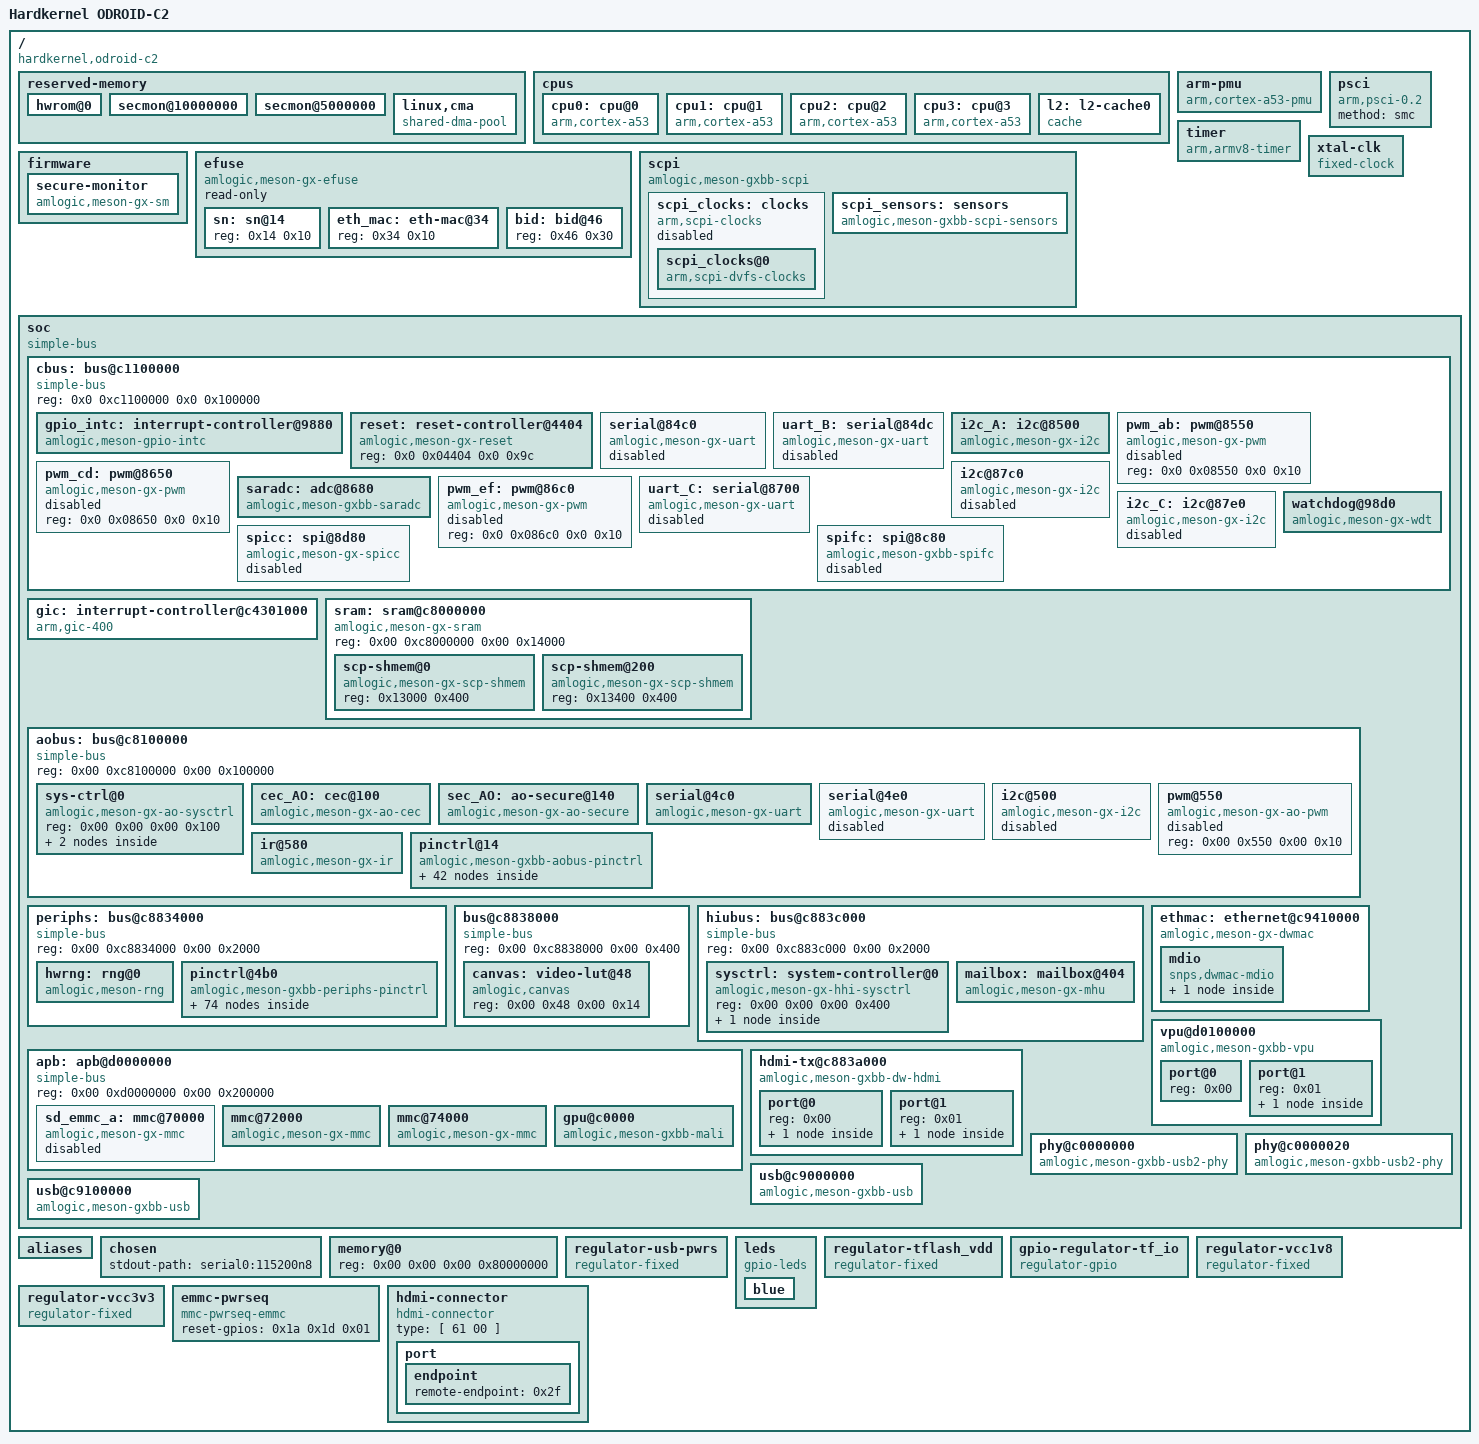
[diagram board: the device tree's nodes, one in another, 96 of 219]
/*
 * Copyright Linux Kernel Team
 *
 * SPDX-License-Identifier: GPL-2.0-only
 *
 * This file is derived from an intermediate build stage of the
 * Linux kernel. The licenses of all input files to this process
 * are compatible with GPL-2.0-only.
 */

/dts-v1/;

/ {
	interrupt-parent = < 0x01 >;
	#address-cells = < 0x02 >;
	#size-cells = < 0x02 >;
	compatible = "hardkernel,odroid-c2", "amlogic,meson-gxbb";
	model = "Hardkernel ODROID-C2";

	reserved-memory {
		#address-cells = <2>;
		#size-cells = <2>;
		ranges;

		/* 16 MiB reserved for Hardware ROM Firmware */
		hwrom@0 {
			reg = < 0x00 0x00 0x00 0x1000000 >;
			no-map;
		};

        /* 2 MiB reserved for ATF/BL31 */
        secmon@10000000 {
			reg = < 0x00 0x10000000 0x00 0x200000 >;
			no-map;
		};

        /* 35 MiB reserved for ATF and TrustZone OS */
		secmon@5000000 {
			reg = < 0x00 0x5000000 0x00 0x2300000 >;
			no-map;
		};

		linux,cma {
			compatible = "shared-dma-pool";
			reusable;
			size = <0x0 0x10000000>;
			alignment = <0x0 0x400000>;
			linux,cma-default;
		};
	};

	cpus {
		#address-cells = <0x2>;
		#size-cells = <0x0>;

		cpu0: cpu@0 {
			device_type = "cpu";
			compatible = "arm,cortex-a53", "arm,armv8";
			reg = <0x0 0x0>;
			enable-method = "psci";
			next-level-cache = < 0x02 >;
			clocks = < 0x03 0x00 >;
			phandle = < 0x04 >;
		};

		cpu1: cpu@1 {
			device_type = "cpu";
			compatible = "arm,cortex-a53", "arm,armv8";
			reg = <0x0 0x1>;
			enable-method = "psci";
			next-level-cache = < 0x02 >;
			clocks = < 0x03 0x00 >;
			phandle = < 0x05 >;
		};

		cpu2: cpu@2 {
			device_type = "cpu";
			compatible = "arm,cortex-a53", "arm,armv8";
			reg = <0x0 0x2>;
			enable-method = "psci";
			next-level-cache = < 0x02 >;
			clocks = < 0x03 0x00 >;
			phandle = < 0x06 >;
		};

		cpu3: cpu@3 {
			device_type = "cpu";
			compatible = "arm,cortex-a53", "arm,armv8";
			reg = < 0x00 0x03 >;
			enable-method = "psci";
			next-level-cache = < 0x02 >;
			clocks = < 0x03 0x00 >;
			phandle = < 0x07 >;
		};

		l2: l2-cache0 {
			compatible = "cache";
			phandle = < 0x02 >;
		};
	};

	arm-pmu {
		compatible = "arm,cortex-a53-pmu";
		interrupts = < 0x00 0x89 0x04 0x00 0x8a 0x04 0x00 0x99 0x04 0x00 0x9a 0x04 >;
		interrupt-affinity = < 0x04 0x05 0x06 0x07 >;
	};

	psci {
		compatible = "arm,psci-0.2";
		method = "smc";
	};

	timer {
		compatible = "arm,armv8-timer";
		interrupts = < 0x01 0x0d 0xff08 0x01 0x0e 0xff08 0x01 0x0b 0xff08 0x01 0x0a 0xff08 >;
	};

	xtal-clk {
		compatible = "fixed-clock";
		clock-frequency = < 0x16e3600 >;
		clock-output-names = "xtal";
		#clock-cells = <0>;
		phandle = < 0x0b >;
	};

	firmware {

		secure-monitor {
			compatible = "amlogic,meson-gx-sm", "amlogic,meson-gxbb-sm";
		};
	};

	efuse: efuse {
		compatible = "amlogic,meson-gx-efuse", "amlogic,meson-gxbb-efuse";
		#address-cells = <1>;
		#size-cells = <1>;
		read-only;

		sn: sn@14 {
			reg = <0x14 0x10>;
		};

		eth_mac: eth-mac@34 {
			reg = <0x34 0x10>;
		};

		bid: bid@46 {
			reg = <0x46 0x30>;
		};
	};

	scpi {
		compatible = "amlogic,meson-gxbb-scpi", "arm,scpi-pre-1.0";
		mboxes = < 0x08 0x01 0x08 0x02 >;
		shmem = < 0x09 0x0a >;

		scpi_clocks: clocks {
			compatible = "arm,scpi-clocks";
			status = "disabled";

			scpi_clocks@0 {
				compatible = "arm,scpi-dvfs-clocks";
				#clock-cells = <1>;
				clock-indices = <0>;
				clock-output-names = "vcpu";
				phandle = < 0x03 >;
			};
		};

		scpi_sensors: sensors {
			compatible = "amlogic,meson-gxbb-scpi-sensors", "arm,scpi-sensors";
			#thermal-sensor-cells = <1>;
		};
	};

	soc {
		compatible = "simple-bus";
		#address-cells = <2>;
		#size-cells = <2>;
		ranges;

		cbus: bus@c1100000 {
			compatible = "simple-bus";
			reg = <0x0 0xc1100000 0x0 0x100000>;
			#address-cells = <2>;
			#size-cells = <2>;
			ranges = <0x0 0x0 0x0 0xc1100000 0x0 0x100000>;

			gpio_intc: interrupt-controller@9880 {
				compatible = "amlogic,meson-gpio-intc", "amlogic,meson-gxbb-gpio-intc";
				reg = <0x0 0x9880 0x0 0x10>;
				interrupt-controller;
				#interrupt-cells = <2>;
				amlogic,channel-interrupts = < 0x40 0x41 0x42 0x43 0x44 0x45 0x46 0x47 >;
				status = "okay";
				phandle = < 0x1b >;
			};

			reset: reset-controller@4404 {
				compatible = "amlogic,meson-gx-reset", "amlogic,meson-gxbb-reset";
				reg = <0x0 0x04404 0x0 0x9c>;
				#reset-cells = <1>;
				phandle = < 0x0f >;
			};

			serial@84c0 {
				compatible = "amlogic,meson-gx-uart";
				reg = <0x0 0x84c0 0x0 0x18>;
				interrupts = < 0x00 0x1a 0x01 >;
				status = "disabled";
				clocks = < 0x0b 0x0c 0x1a 0x0b >;
				clock-names = "xtal", "pclk", "baud";
			};

			uart_B: serial@84dc {
				compatible = "amlogic,meson-gx-uart";
				reg = <0x0 0x84dc 0x0 0x18>;
				interrupts = < 0x00 0x4b 0x01 >;
				status = "disabled";
				clocks = < 0x0b 0x0c 0x30 0x0b >;
				clock-names = "xtal", "pclk", "baud";
			};

			i2c_A: i2c@8500 {
				compatible = "amlogic,meson-gx-i2c", "amlogic,meson-gxbb-i2c";
				reg = <0x0 0x08500 0x0 0x20>;
				interrupts = < 0x00 0x15 0x01 >;
				#address-cells = < 0x01 >;
				#size-cells = <0>;
				status = "okay";
				clocks = < 0x0c 0x16 >;
				pinctrl-0 = < 0x0d >;
				pinctrl-names = "default";
			};

			pwm_ab: pwm@8550 {
				compatible = "amlogic,meson-gx-pwm", "amlogic,meson-gxbb-pwm";
				reg = <0x0 0x08550 0x0 0x10>;
				#pwm-cells = <3>;
				status = "disabled";
			};

			pwm_cd: pwm@8650 {
				compatible = "amlogic,meson-gx-pwm", "amlogic,meson-gxbb-pwm";
				reg = <0x0 0x08650 0x0 0x10>;
				#pwm-cells = <3>;
				status = "disabled";
			};

			saradc: adc@8680 {
				compatible = "amlogic,meson-gxbb-saradc", "amlogic,meson-saradc";
				reg = <0x0 0x8680 0x0 0x34>;
				#io-channel-cells = <1>;
				interrupts = < 0x00 0x49 0x01 >;
				status = "okay";
				clocks = < 0x0b 0x0c 0x17 0x0c 0x61 0x0c 0x62 >;
				clock-names = "clkin", "core", "adc_clk", "adc_sel";
				vref-supply = < 0x0e >;
			};

			pwm_ef: pwm@86c0 {
				compatible = "amlogic,meson-gx-pwm", "amlogic,meson-gxbb-pwm";
				reg = <0x0 0x086c0 0x0 0x10>;
				#pwm-cells = <3>;
				status = "disabled";
			};

			uart_C: serial@8700 {
				compatible = "amlogic,meson-gx-uart";
				reg = <0x0 0x8700 0x0 0x18>;
				interrupts = < 0x00 0x5d 0x01 >;
				status = "disabled";
				clocks = < 0x0b 0x0c 0x44 0x0b >;
				clock-names = "xtal", "pclk", "baud";
			};

			i2c@87c0 {
				compatible = "amlogic,meson-gx-i2c", "amlogic,meson-gxbb-i2c";
				reg = < 0x00 0x87c0 0x00 0x20 >;
				interrupts = < 0x00 0xd6 0x01 >;
				#address-cells = < 0x01 >;
				#size-cells = < 0x00 >;
				status = "disabled";
				clocks = < 0x0c 0x16 >;
			};

			i2c_C: i2c@87e0 {
				compatible = "amlogic,meson-gx-i2c", "amlogic,meson-gxbb-i2c";
				reg = < 0x00 0x87e0 0x00 0x20 >;
				interrupts = < 0x00 0xd7 0x01 >;
				#address-cells = < 0x01 >;
				#size-cells = < 0x00 >;
				status = "disabled";
				clocks = < 0x0c 0x16 >;
			};

			spicc: spi@8d80 {
				compatible = "amlogic,meson-gx-spicc";
				reg = < 0x00 0x8d80 0x00 0x80 >;
				interrupts = < 0x00 0x51 0x04 >;
				#address-cells = < 0x01 >;
				#size-cells = < 0x00 >;
				status = "disabled";
				clocks = < 0x0c 0x15 >;
				clock-names = "core";
				resets = < 0x0f 0xc1 >;
				num-cs = < 0x01 >;
			};

			spifc: spi@8c80 {
				compatible = "amlogic,meson-gxbb-spifc";
				reg = < 0x00 0x8c80 0x00 0x80 >;
				#address-cells = < 0x01 >;
				#size-cells = < 0x00 >;
				status = "disabled";
				clocks = < 0x0c 0x22 >;
			};

			watchdog@98d0 {
				compatible = "amlogic,meson-gx-wdt", "amlogic,meson-gxbb-wdt";
				reg = < 0x00 0x98d0 0x00 0x10 >;
				clocks = < 0x0b >;
			};
		};

		gic: interrupt-controller@c4301000 {
			compatible = "arm,gic-400";
			reg = < 0x00 0xc4301000 0x00 0x1000 0x00 0xc4302000 0x00 0x2000 0x00 0xc4304000 0x00 0x2000 0x00 0xc4306000 0x00 0x2000 >;
			interrupt-controller;
			interrupts = < 0x01 0x09 0xff04 >;
			#interrupt-cells = < 0x03 >;
			#address-cells = < 0x00 >;
			phandle = < 0x01 >;
		};

		sram: sram@c8000000 {
			compatible = "amlogic,meson-gx-sram", "amlogic,meson-gxbb-sram", "mmio-sram";
			reg = < 0x00 0xc8000000 0x00 0x14000 >;
			#address-cells = < 0x01 >;
			#size-cells = < 0x01 >;
			ranges = < 0x00 0x00 0xc8000000 0x14000 >;

			scp-shmem@0 {
				compatible = "amlogic,meson-gx-scp-shmem", "amlogic,meson-gxbb-scp-shmem";
				reg = < 0x13000 0x400 >;
				phandle = < 0x09 >;
			};

			scp-shmem@200 {
				compatible = "amlogic,meson-gx-scp-shmem", "amlogic,meson-gxbb-scp-shmem";
				reg = < 0x13400 0x400 >;
				phandle = < 0x0a >;
			};
		};

		aobus: bus@c8100000 {
			compatible = "simple-bus";
			reg = < 0x00 0xc8100000 0x00 0x100000 >;
			#address-cells = < 0x02 >;
			#size-cells = < 0x02 >;
			ranges = < 0x00 0x00 0x00 0xc8100000 0x00 0x100000 >;

			sys-ctrl@0 {
				compatible = "amlogic,meson-gx-ao-sysctrl", "simple-mfd", "syscon";
				reg = < 0x00 0x00 0x00 0x100 >;

				power-controller-vpu {
					compatible = "amlogic,meson-gx-pwrc-vpu";
					#power-domain-cells = < 0x00 >;
					amlogic,hhi-sysctrl = < 0x10 >;
					resets = < 0x0f 0x05 0x0f 0x0a 0x0f 0x0d 0x0f 0x25 0x0f 0x84 0x0f 0x85 0x0f 0x86 0x0f 0x87 0x0f 0x89 0x0f 0x8c 0x0f 0x8d 0x0f 0xe7 >;
					clocks = < 0x0c 0x84 0x0c 0x8c >;
					clock-names = "vpu", "vapb";
					assigned-clocks = < 0x0c 0x7e 0x0c 0x80 0x0c 0x84 0x0c 0x85 0x0c 0x87 0x0c 0x8b >;
					assigned-clock-parents = < 0x0c 0x05 0x00 0x0c 0x80 0x0c 0x06 0x00 0x0c 0x87 >;
					assigned-clock-rates = < 0x00 0x27bc86aa 0x00 0x00 0xee6b280 0x00 >;
					phandle = < 0x25 >;
				};

				clkc_AO: clock-controller {
					compatible = "amlogic,meson-gxbb-aoclkc", "amlogic,meson-gx-aoclkc";
					#clock-cells = < 0x01 >;
					#reset-cells = < 0x01 >;
					phandle = < 0x11 >;
				};
			};

			cec_AO: cec@100 {
				compatible = "amlogic,meson-gx-ao-cec";
				reg = < 0x00 0x100 0x00 0x14 >;
				interrupts = < 0x00 0xc7 0x01 >;
				clocks = < 0x11 0x06 >;
				clock-names = "core";
				status = "okay";
				pinctrl-0 = < 0x12 >;
				pinctrl-names = "default";
				hdmi-phandle = < 0x13 >;
			};

			sec_AO: ao-secure@140 {
				compatible = "amlogic,meson-gx-ao-secure", "syscon";
				reg = < 0x00 0x140 0x00 0x140 >;
				amlogic,has-chip-id;
			};

			serial@4c0 {
				compatible = "amlogic,meson-gx-uart", "amlogic,meson-ao-uart";
				reg = < 0x00 0x4c0 0x00 0x18 >;
				interrupts = < 0x00 0xc1 0x01 >;
				status = "okay";
				clocks = < 0x0b 0x11 0x03 0x0b >;
				clock-names = "xtal", "pclk", "baud";
				pinctrl-0 = < 0x14 >;
				pinctrl-names = "default";
			};

			serial@4e0 {
				compatible = "amlogic,meson-gx-uart", "amlogic,meson-ao-uart";
				reg = < 0x00 0x4e0 0x00 0x18 >;
				interrupts = < 0x00 0xc5 0x01 >;
				status = "disabled";
				clocks = < 0x0b 0x11 0x04 0x0b >;
				clock-names = "xtal", "pclk", "baud";
			};

			i2c@500 {
				compatible = "amlogic,meson-gx-i2c", "amlogic,meson-gxbb-i2c";
				reg = < 0x00 0x500 0x00 0x20 >;
				interrupts = < 0x00 0xc3 0x01 >;
				#address-cells = < 0x01 >;
				#size-cells = < 0x00 >;
				status = "disabled";
				clocks = < 0x0c 0x5d >;
			};

			pwm@550 {
				compatible = "amlogic,meson-gx-ao-pwm", "amlogic,meson-gxbb-ao-pwm";
				reg = < 0x00 0x550 0x00 0x10 >;
				#pwm-cells = < 0x03 >;
				status = "disabled";
			};

			ir@580 {
				compatible = "amlogic,meson-gx-ir", "amlogic,meson-gxbb-ir";
				reg = < 0x00 0x580 0x00 0x40 >;
				interrupts = < 0x00 0xc4 0x01 >;
				status = "okay";
				pinctrl-0 = < 0x15 >;
				pinctrl-names = "default";
			};

			pinctrl@14 {
				compatible = "amlogic,meson-gxbb-aobus-pinctrl";
				#address-cells = < 0x02 >;
				#size-cells = < 0x02 >;
				ranges;
				gpio-line-names = "UART TX", "UART RX", "VCCK En", "TF 3V3/1V8 En", "USB HUB nRESET", "USB OTG Power En", "J7 Header Pin2", "IR In", "J7 Header Pin4", "J7 Header Pin6", "J7 Header Pin5", "J7 Header Pin7", "HDMI CEC", "SYS LED", "";
				phandle = < 0x16 >;

				bank@14 {
					reg = < 0x00 0x14 0x00 0x08 0x00 0x2c 0x00 0x04 0x00 0x24 0x00 0x08 >;
					reg-names = "mux", "pull", "gpio";
					gpio-controller;
					#gpio-cells = < 0x02 >;
					gpio-ranges = < 0x16 0x00 0x00 0x0e >;
					phandle = < 0x2e >;

					usb-hub {
						gpio-hog;
						gpios = < 0x04 0x00 >;
						output-high;
						line-name = "usb-hub-reset";
					};
				};

				uart_ao_a {
					phandle = < 0x14 >;

					mux {
						groups = "uart_tx_ao_a", "uart_rx_ao_a";
						function = "uart_ao";
					};
				};

				uart_ao_a_cts_rts {

					mux {
						groups = "uart_cts_ao_a", "uart_rts_ao_a";
						function = "uart_ao";
					};
				};

				uart_ao_b {

					mux {
						groups = "uart_tx_ao_b", "uart_rx_ao_b";
						function = "uart_ao_b";
					};
				};

				uart_ao_b_cts_rts {

					mux {
						groups = "uart_cts_ao_b", "uart_rts_ao_b";
						function = "uart_ao_b";
					};
				};

				remote_input_ao {
					phandle = < 0x15 >;

					mux {
						groups = "remote_input_ao";
						function = "remote_input_ao";
					};
				};

				i2c_ao {

					mux {
						groups = "i2c_sck_ao", "i2c_sda_ao";
						function = "i2c_ao";
					};
				};

				pwm_ao_a_3 {

					mux {
						groups = "pwm_ao_a_3";
						function = "pwm_ao_a_3";
					};
				};

				pwm_ao_a_6 {

					mux {
						groups = "pwm_ao_a_6";
						function = "pwm_ao_a_6";
					};
				};

				pwm_ao_a_12 {

					mux {
						groups = "pwm_ao_a_12";
						function = "pwm_ao_a_12";
					};
				};

				pwm_ao_b {

					mux {
						groups = "pwm_ao_b";
						function = "pwm_ao_b";
					};
				};

				i2s_am_clk {

					mux {
						groups = "i2s_am_clk";
						function = "i2s_out_ao";
					};
				};

				i2s_out_ao_clk {

					mux {
						groups = "i2s_out_ao_clk";
						function = "i2s_out_ao";
					};
				};

				i2s_out_lr_clk {

					mux {
						groups = "i2s_out_lr_clk";
						function = "i2s_out_ao";
					};
				};

				i2s_out_ch01_ao {

					mux {
						groups = "i2s_out_ch01_ao";
						function = "i2s_out_ao";
					};
				};

				i2s_out_ch23_ao {

					mux {
						groups = "i2s_out_ch23_ao";
						function = "i2s_out_ao";
					};
				};

				i2s_out_ch45_ao {

					mux {
						groups = "i2s_out_ch45_ao";
						function = "i2s_out_ao";
					};
				};

				spdif_out_ao_6 {

					mux {
						groups = "spdif_out_ao_6";
						function = "spdif_out_ao";
					};
				};

				spdif_out_ao_13 {

					mux {
						groups = "spdif_out_ao_13";
						function = "spdif_out_ao";
					};
				};

				ao_cec {
					phandle = < 0x12 >;

					mux {
						groups = "ao_cec";
						function = "cec_ao";
					};
				};

				ee_cec {

					mux {
						groups = "ee_cec";
						function = "cec_ao";
					};
				};
			};
		};

		periphs: bus@c8834000 {
			compatible = "simple-bus";
			reg = < 0x00 0xc8834000 0x00 0x2000 >;
			#address-cells = < 0x02 >;
			#size-cells = < 0x02 >;
			ranges = < 0x00 0x00 0x00 0xc8834000 0x00 0x2000 >;

			hwrng: rng@0 {
				compatible = "amlogic,meson-rng";
				reg = < 0x00 0x00 0x00 0x04 >;
				clocks = < 0x0c 0x19 >;
				clock-names = "core";
			};

			pinctrl@4b0 {
				compatible = "amlogic,meson-gxbb-periphs-pinctrl";
				#address-cells = < 0x02 >;
				#size-cells = < 0x02 >;
				ranges;
				gpio-line-names = "Eth MDIO", "Eth MDC", "Eth RGMII RX Clk", "Eth RX DV", "Eth RX D0", "Eth RX D1", "Eth RX D2", "Eth RX D3", "Eth RGMII TX Clk", "Eth TX En", "Eth TX D0", "Eth TX D1", "Eth TX D2", "Eth TX D3", "Eth PHY nRESET", "Eth PHY Intc", "HDMI HPD", "HDMI DDC SDA", "HDMI DDC SCL", "", "eMMC D0", "eMMC D1", "eMMC D2", "eMMC D3", "eMMC D4", "eMMC D5", "eMMC D6", "eMMC D7", "eMMC Clk", "eMMC Reset", "eMMC CMD", "", "", "", "", "", "", "", "SDCard D1", "SDCard D0", "SDCard CLK", "SDCard CMD", "SDCard D3", "SDCard D2", "SDCard Det", "", "", "", "", "", "", "", "", "", "", "", "", "", "", "", "", "", "", "", "", "", "", "", "", "I2C A SDA", "I2C A SCK", "I2C B SDA", "I2C B SCK", "PWM D", "PWM B", "Revision Bit0", "Revision Bit1", "", "J2 Header Pin35", "", "", "", "J2 Header Pin36", "J2 Header Pin31", "", "", "", "TF VDD En", "J2 Header Pin32", "J2 Header Pin26", "", "", "J2 Header Pin29", "J2 Header Pin24", "J2 Header Pin23", "J2 Header Pin22", "J2 Header Pin21", "J2 Header Pin18", "J2 Header Pin33", "J2 Header Pin19", "J2 Header Pin16", "J2 Header Pin15", "J2 Header Pin12", "J2 Header Pin13", "J2 Header Pin8", "J2 Header Pin10", "", "", "", "", "", "J2 Header Pin11", "", "J2 Header Pin7", "", "", "", "", "";
				phandle = < 0x17 >;

				bank@4b0 {
					reg = < 0x00 0x4b0 0x00 0x28 0x00 0x4e8 0x00 0x14 0x00 0x520 0x00 0x14 0x00 0x430 0x00 0x40 >;
					reg-names = "mux", "pull", "pull-enable", "gpio";
					gpio-controller;
					#gpio-cells = < 0x02 >;
					gpio-ranges = < 0x17 0x00 0x00 0x77 >;
					phandle = < 0x1a >;
				};

				emmc {
					phandle = < 0x20 >;

					mux {
						groups = "emmc_nand_d07", "emmc_cmd", "emmc_clk";
						function = "emmc";
					};
				};

				emmc-ds {
					phandle = < 0x21 >;

					mux {
						groups = "emmc_ds";
						function = "emmc";
					};
				};

				emmc_clk_gate {
					phandle = < 0x22 >;

					mux {
						groups = "BOOT_8";
						function = "gpio_periphs";
					};

					cfg-pull-down {
						pins = "BOOT_8";
						bias-pull-down;
					};
				};

				nor {

					mux {
						groups = "nor_d", "nor_q", "nor_c", "nor_cs";
						function = "nor";
					};
				};

				spi-pins {

					mux {
						groups = "spi_miso", "spi_mosi", "spi_sclk";
						function = "spi";
					};
				};

				spi-ss0 {

					mux {
						groups = "spi_ss0";
						function = "spi";
					};
				};

				sdcard {
					phandle = < 0x1c >;

					mux {
						groups = "sdcard_d0", "sdcard_d1", "sdcard_d2", "sdcard_d3", "sdcard_cmd", "sdcard_clk";
						function = "sdcard";
					};
				};

				sdcard_clk_gate {
					phandle = < 0x1d >;

					mux {
						groups = "CARD_2";
						function = "gpio_periphs";
					};

					cfg-pull-down {
						pins = "CARD_2";
						bias-pull-down;
					};
				};

				sdio {

					mux {
						groups = "sdio_d0", "sdio_d1", "sdio_d2", "sdio_d3", "sdio_cmd", "sdio_clk";
						function = "sdio";
					};
				};

				sdio_clk_gate {

					mux {
						groups = "GPIOX_4";
						function = "gpio_periphs";
					};

					cfg-pull-down {
						pins = "GPIOX_4";
						bias-pull-down;
					};
				};

				sdio_irq {

					mux {
						groups = "sdio_irq";
						function = "sdio";
					};
				};

				uart_a {

					mux {
						groups = "uart_tx_a", "uart_rx_a";
						function = "uart_a";
					};
				};

				uart_a_cts_rts {

					mux {
						groups = "uart_cts_a", "uart_rts_a";
						function = "uart_a";
					};
				};

				uart_b {

					mux {
						groups = "uart_tx_b", "uart_rx_b";
						function = "uart_b";
					};
				};

				uart_b_cts_rts {

					mux {
						groups = "uart_cts_b", "uart_rts_b";
						function = "uart_b";
					};
				};

				uart_c {

					mux {
						groups = "uart_tx_c", "uart_rx_c";
						function = "uart_c";
					};
				};

				uart_c_cts_rts {

					mux {
						groups = "uart_cts_c", "uart_rts_c";
						function = "uart_c";
					};
				};

				i2c_a {
					phandle = < 0x0d >;

					mux {
						groups = "i2c_sck_a", "i2c_sda_a";
						function = "i2c_a";
					};
				};

				i2c_b {

					mux {
						groups = "i2c_sck_b", "i2c_sda_b";
						function = "i2c_b";
					};
				};

				i2c_c {

					mux {
						groups = "i2c_sck_c", "i2c_sda_c";
						function = "i2c_c";
					};
				};

				eth-rgmii {
					phandle = < 0x18 >;

					mux {
						groups = "eth_mdio", "eth_mdc", "eth_clk_rx_clk", "eth_rx_dv", "eth_rxd0", "eth_rxd1", "eth_rxd2", "eth_rxd3", "eth_rgmii_tx_clk", "eth_tx_en", "eth_txd0", "eth_txd1", "eth_txd2", "eth_txd3";
						function = "eth";
					};
				};

				eth-rmii {

					mux {
						groups = "eth_mdio", "eth_mdc", "eth_clk_rx_clk", "eth_rx_dv", "eth_rxd0", "eth_rxd1", "eth_tx_en", "eth_txd0", "eth_txd1";
						function = "eth";
					};
				};

				pwm_a_x {

					mux {
						groups = "pwm_a_x";
						function = "pwm_a_x";
					};
				};

				pwm_a_y {

					mux {
						groups = "pwm_a_y";
						function = "pwm_a_y";
					};
				};

				pwm_b {

					mux {
						groups = "pwm_b";
						function = "pwm_b";
					};
				};

				pwm_d {

					mux {
						groups = "pwm_d";
						function = "pwm_d";
					};
				};

				pwm_e {

					mux {
						groups = "pwm_e";
						function = "pwm_e";
					};
				};

				pwm_f_x {

					mux {
						groups = "pwm_f_x";
						function = "pwm_f_x";
					};
				};

				pwm_f_y {

					mux {
						groups = "pwm_f_y";
						function = "pwm_f_y";
					};
				};

				hdmi_hpd {
					phandle = < 0x27 >;

					mux {
						groups = "hdmi_hpd";
						function = "hdmi_hpd";
					};
				};

				hdmi_i2c {
					phandle = < 0x28 >;

					mux {
						groups = "hdmi_sda", "hdmi_scl";
						function = "hdmi_i2c";
					};
				};

				i2sout_ch23_y {

					mux {
						groups = "i2sout_ch23_y";
						function = "i2s_out";
					};
				};

				i2sout_ch45_y {

					mux {
						groups = "i2sout_ch45_y";
						function = "i2s_out";
					};
				};

				i2sout_ch67_y {

					mux {
						groups = "i2sout_ch67_y";
						function = "i2s_out";
					};
				};

				spdif_out_y {

					mux {
						groups = "spdif_out_y";
						function = "spdif_out";
					};
				};
			};
		};

		bus@c8838000 {
			compatible = "simple-bus";
			reg = < 0x00 0xc8838000 0x00 0x400 >;
			#address-cells = < 0x02 >;
			#size-cells = < 0x02 >;
			ranges = < 0x00 0x00 0x00 0xc8838000 0x00 0x400 >;

			canvas: video-lut@48 {
				compatible = "amlogic,canvas";
				reg = < 0x00 0x48 0x00 0x14 >;
			};
		};

		hiubus: bus@c883c000 {
			compatible = "simple-bus";
			reg = < 0x00 0xc883c000 0x00 0x2000 >;
			#address-cells = < 0x02 >;
			#size-cells = < 0x02 >;
			ranges = < 0x00 0x00 0x00 0xc883c000 0x00 0x2000 >;

			sysctrl: system-controller@0 {
				compatible = "amlogic,meson-gx-hhi-sysctrl", "simple-mfd", "syscon";
				reg = < 0x00 0x00 0x00 0x400 >;
				phandle = < 0x10 >;

				pwrc: power-controller {
					compatible = "amlogic,gxbb-clkc";
					#clock-cells = < 0x01 >;
					phandle = < 0x0c >;
				};
			};

			mailbox: mailbox@404 {
				compatible = "amlogic,meson-gx-mhu", "amlogic,meson-gxbb-mhu";
				reg = < 0x00 0x404 0x00 0x4c >;
				interrupts = < 0x00 0xd0 0x01 0x00 0xd1 0x01 0x00 0xd2 0x01 >;
				#mbox-cells = < 0x01 >;
				phandle = < 0x08 >;
			};
		};

		ethmac: ethernet@c9410000 {
			compatible = "amlogic,meson-gx-dwmac", "amlogic,meson-gxbb-dwmac", "snps,dwmac";
			reg = < 0x00 0xc9410000 0x00 0x10000 0x00 0xc8834540 0x00 0x04 >;
			interrupts = < 0x00 0x08 0x01 >;
			interrupt-names = "macirq";
			status = "okay";
			clocks = < 0x0c 0x24 0x0c 0x04 0x0c 0x0f >;
			clock-names = "stmmaceth", "clkin0", "clkin1";
			pinctrl-0 = < 0x18 >;
			pinctrl-names = "default";
			phy-handle = < 0x19 >;
			phy-mode = "rgmii";
			snps,reset-gpio = < 0x1a 0x0e 0x00 >;
			snps,reset-delays-us = < 0x00 0x2710 0xf4240 >;
			snps,reset-active-low;
			amlogic,tx-delay-ns = < 0x02 >;

			mdio {
				compatible = "snps,dwmac-mdio";
				#address-cells = < 0x01 >;
				#size-cells = < 0x00 >;

				ethernet-phy@0 {
					reg = < 0x00 >;
					interrupt-parent = < 0x1b >;
					interrupts = < 0x1d 0x08 >;
					eee-broken-1000t;
					phandle = < 0x19 >;
				};
			};
		};

		apb: apb@d0000000 {
			compatible = "simple-bus";
			reg = < 0x00 0xd0000000 0x00 0x200000 >;
			#address-cells = < 0x02 >;
			#size-cells = < 0x02 >;
			ranges = < 0x00 0x00 0x00 0xd0000000 0x00 0x200000 >;

			sd_emmc_a: mmc@70000 {
				compatible = "amlogic,meson-gx-mmc", "amlogic,meson-gxbb-mmc";
				reg = < 0x00 0x70000 0x00 0x800 >;
				interrupts = < 0x00 0xd8 0x01 >;
				status = "disabled";
				clocks = < 0x0c 0x5e 0x0c 0x77 0x0c 0x04 >;
				clock-names = "core", "clkin0", "clkin1";
				resets = < 0x0f 0x2c >;
			};

			mmc@72000 {
				compatible = "amlogic,meson-gx-mmc", "amlogic,meson-gxbb-mmc";
				reg = < 0x00 0x72000 0x00 0x800 >;
				interrupts = < 0x00 0xd9 0x01 >;
				status = "okay";
				clocks = < 0x0c 0x5f 0x0c 0x7a 0x0c 0x04 >;
				clock-names = "core", "clkin0", "clkin1";
				resets = < 0x0f 0x2d >;
				pinctrl-0 = < 0x1c >;
				pinctrl-1 = < 0x1d >;
				pinctrl-names = "default", "clk-gate";
				bus-width = < 0x04 >;
				cap-sd-highspeed;
				max-frequency = < 0x5f5e100 >;
				disable-wp;
				cd-gpios = < 0x1a 0x2c 0x00 >;
				cd-inverted;
				vmmc-supply = < 0x1e >;
				vqmmc-supply = < 0x1f >;
			};

			mmc@74000 {
				compatible = "amlogic,meson-gx-mmc", "amlogic,meson-gxbb-mmc";
				reg = < 0x00 0x74000 0x00 0x800 >;
				interrupts = < 0x00 0xda 0x01 >;
				status = "okay";
				clocks = < 0x0c 0x60 0x0c 0x7d 0x0c 0x04 >;
				clock-names = "core", "clkin0", "clkin1";
				resets = < 0x0f 0x2e >;
				pinctrl-0 = < 0x20 0x21 >;
				pinctrl-1 = < 0x22 >;
				pinctrl-names = "default", "clk-gate";
				bus-width = < 0x08 >;
				max-frequency = < 0x5f5e100 >;
				non-removable;
				disable-wp;
				cap-mmc-highspeed;
				mmc-ddr-1_8v;
				mmc-hs200-1_8v;
				mmc-pwrseq = < 0x23 >;
				vmmc-supply = < 0x24 >;
				vqmmc-supply = < 0x0e >;
			};

			gpu@c0000 {
				compatible = "amlogic,meson-gxbb-mali", "arm,mali-450";
				reg = < 0x00 0xc0000 0x00 0x40000 >;
				interrupts = < 0x00 0xa0 0x04 0x00 0xa1 0x04 0x00 0xa2 0x04 0x00 0xa3 0x04 0x00 0xa4 0x04 0x00 0xa5 0x04 0x00 0xa6 0x04 0x00 0xa7 0x04 0x00 0xa8 0x04 0x00 0xa9 0x04 >;
				interrupt-names = "gp", "gpmmu", "pp", "pmu", "pp0", "ppmmu0", "pp1", "ppmmu1", "pp2", "ppmmu2";
				clocks = < 0x0c 0x0c 0x0c 0x6a >;
				clock-names = "bus", "core";
				assigned-clocks = < 0x0c 0x09 0x0c 0x64 0x0c 0x66 0x0c 0x6a >;
				assigned-clock-parents = < 0x00 0x0c 0x09 0x00 0x0c 0x66 >;
				assigned-clock-rates = < 0x2c588a00 0x00 0x2c588a00 0x00 >;
			};
		};

		vpu@d0100000 {
			compatible = "amlogic,meson-gxbb-vpu", "amlogic,meson-gx-vpu";
			reg = < 0x00 0xd0100000 0x00 0x100000 0x00 0xc883c000 0x00 0x1000 0x00 0xc8838000 0x00 0x1000 >;
			reg-names = "vpu", "hhi", "dmc";
			interrupts = < 0x00 0x03 0x01 >;
			#address-cells = < 0x01 >;
			#size-cells = < 0x00 >;
			power-domains = < 0x25 >;

			port@0 {
				reg = < 0x00 >;
			};

			port@1 {
				reg = < 0x01 >;

				endpoint {
					remote-endpoint = < 0x26 >;
					phandle = < 0x29 >;
				};
			};
		};

		hdmi-tx@c883a000 {
			compatible = "amlogic,meson-gxbb-dw-hdmi", "amlogic,meson-gx-dw-hdmi";
			reg = < 0x00 0xc883a000 0x00 0x1c >;
			interrupts = < 0x00 0x39 0x01 >;
			#address-cells = < 0x01 >;
			#size-cells = < 0x00 >;
			status = "okay";
			resets = < 0x0f 0x13 0x0f 0x4f 0x0f 0x42 >;
			reset-names = "hdmitx_apb", "hdmitx", "hdmitx_phy";
			clocks = < 0x0c 0x3f 0x0c 0x0c 0x0c 0x4d >;
			clock-names = "isfr", "iahb", "venci";
			pinctrl-0 = < 0x27 0x28 >;
			pinctrl-names = "default";
			phandle = < 0x13 >;

			port@0 {
				reg = < 0x00 >;

				endpoint {
					remote-endpoint = < 0x29 >;
					phandle = < 0x26 >;
				};
			};

			port@1 {
				reg = < 0x01 >;

				endpoint {
					remote-endpoint = < 0x2a >;
					phandle = < 0x2f >;
				};
			};
		};

		phy@c0000000 {
			compatible = "amlogic,meson-gxbb-usb2-phy";
			#phy-cells = < 0x00 >;
			reg = < 0x00 0xc0000000 0x00 0x20 >;
			resets = < 0x0f 0x22 >;
			clocks = < 0x0c 0x37 0x0c 0x32 >;
			clock-names = "usb_general", "usb";
			status = "okay";
			phy-supply = < 0x2b >;
			phandle = < 0x2c >;
		};

		phy@c0000020 {
			compatible = "amlogic,meson-gxbb-usb2-phy";
			#phy-cells = < 0x00 >;
			reg = < 0x00 0xc0000020 0x00 0x20 >;
			resets = < 0x0f 0x22 >;
			clocks = < 0x0c 0x37 0x0c 0x33 >;
			clock-names = "usb_general", "usb";
			status = "okay";
			phy-supply = < 0x2b >;
			phandle = < 0x2d >;
		};

		usb@c9000000 {
			compatible = "amlogic,meson-gxbb-usb", "snps,dwc2";
			reg = < 0x00 0xc9000000 0x00 0x40000 >;
			interrupts = < 0x00 0x1e 0x04 >;
			clocks = < 0x0c 0x41 >;
			clock-names = "otg";
			phys = < 0x2c >;
			phy-names = "usb2-phy";
			dr_mode = "host";
			status = "okay";
		};

		usb@c9100000 {
			compatible = "amlogic,meson-gxbb-usb", "snps,dwc2";
			reg = < 0x00 0xc9100000 0x00 0x40000 >;
			interrupts = < 0x00 0x1f 0x04 >;
			clocks = < 0x0c 0x40 >;
			clock-names = "otg";
			phys = < 0x2d >;
			phy-names = "usb2-phy";
			dr_mode = "host";
			status = "okay";
		};
	};

	aliases {
		serial0 = "/soc/bus@c8100000/serial@4c0";
		ethernet0 = "/soc/ethernet@c9410000";
	};

	chosen {
		stdout-path = "serial0:115200n8";
	};

	memory@0 {
		device_type = "memory";
		reg = < 0x00 0x00 0x00 0x80000000 >;
	};

	regulator-usb-pwrs {
		compatible = "regulator-fixed";
		regulator-name = "USB_OTG_PWR";
		regulator-min-microvolt = < 0x4c4b40 >;
		regulator-max-microvolt = < 0x4c4b40 >;
		gpio = < 0x2e 0x05 0x00 >;
		enable-active-high;
		phandle = < 0x2b >;
	};

	leds {
		compatible = "gpio-leds";

		blue {
			label = "c2:blue:alive";
			gpios = < 0x2e 0x0d 0x01 >;
			linux,default-trigger = "heartbeat";
			default-state = "off";
		};
	};

	regulator-tflash_vdd {
		compatible = "regulator-fixed";
		regulator-name = "TFLASH_VDD";
		regulator-min-microvolt = < 0x325aa0 >;
		regulator-max-microvolt = < 0x325aa0 >;
		gpio = < 0x1a 0x57 0x00 >;
		enable-active-high;
		phandle = < 0x1e >;
	};

	gpio-regulator-tf_io {
		compatible = "regulator-gpio";
		regulator-name = "TF_IO";
		regulator-min-microvolt = < 0x1b7740 >;
		regulator-max-microvolt = < 0x325aa0 >;
		gpios = < 0x2e 0x03 0x00 >;
		gpios-states = < 0x00 >;
		states = < 0x325aa0 0x00 0x1b7740 0x01 >;
		phandle = < 0x1f >;
	};

	regulator-vcc1v8 {
		compatible = "regulator-fixed";
		regulator-name = "VCC1V8";
		regulator-min-microvolt = < 0x1b7740 >;
		regulator-max-microvolt = < 0x1b7740 >;
		phandle = < 0x0e >;
	};

	regulator-vcc3v3 {
		compatible = "regulator-fixed";
		regulator-name = "VCC3V3";
		regulator-min-microvolt = < 0x325aa0 >;
		regulator-max-microvolt = < 0x325aa0 >;
		phandle = < 0x24 >;
	};

	emmc-pwrseq {
		compatible = "mmc-pwrseq-emmc";
		reset-gpios = < 0x1a 0x1d 0x01 >;
		phandle = < 0x23 >;
	};

	hdmi-connector {
		compatible = "hdmi-connector";
		type = [ 61 00 ];

		port {

			endpoint {
				remote-endpoint = < 0x2f >;
				phandle = < 0x2a >;
			};
		};
	};
};
